# bcm2837_lpa register map
Vendor: BROADCOM; Series: BCM2837; File version: A
CPU: CA72 r0p0, little endian, MPU, FPU, 2 interrupt priority bits
Registers are 32-bit, read-write, reset 0x0 unless marked. A register's access mark holds for its fields unless they carry their own. Offsets are from the block's base; [hi:lo] are bit positions; {n}, {i} and the like mark numbered series.

## SPI0 — Broadcom SPI Controller
Base 0x3F204000
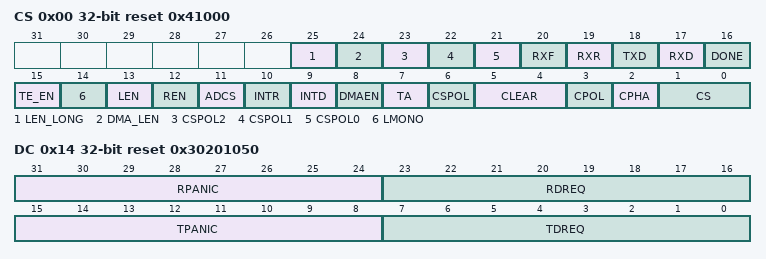
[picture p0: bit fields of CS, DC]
0x00 CS reset 0x41000 — Control and Status
  [25] LEN_LONG — Enable long data word in LoSSI mode
  [24] DMA_LEN — Enable DMA in LoSSI mode
  [23] CSPOL2 — Chip select 2 polarity
  [22] CSPOL1 — Chip select 1 polarity
  [21] CSPOL0 — Chip select 0 polarity
  [20] RXF ro — RX FIFO full
  [19] RXR ro — RX FIFO has data to be read
  [18] TXD ro — TX FIFO can accept data
  [17] RXD ro — RX FIFO contains data
  [16] DONE ro — Transfer is done
  [15] TE_EN
  [14] LMONO
  [13] LEN — LoSSI enable
  [12] REN — Read enable
  [11] ADCS — Automatically deassert chip select
  [10] INTR — Interrupt on RX
  [9] INTD — Interrupt on done
  [8] DMAEN — Enable DMA
  [7] TA — Transfer active
  [6] CSPOL — Chip select polarity
  [5:4] CLEAR — Clear the FIFO(s)
    1=TX; 2=RX; 3=BOTH
  [3] CPOL — Clock polarity
  [2] CPHA — Clock phase
  [1:0] CS — Chip select
0x04 FIFO — FIFO access
  [31:0] DATA
0x08 CLK — Clock divider
  [15:0] CDIV
0x0C DLEN — Data length
  [15:0] DLEN
0x10 LTOH reset 0x1 — LoSSI output hold delay
  [3:0] TOH — Output hold delay
0x14 DC reset 0x30201050
  [31:24] RPANIC — DMA read panic threshold
  [23:16] RDREQ — DMA read request threshold
  [15:8] TPANIC — DMA write panic threshold
  [7:0] TDREQ — DMA Write request threshold

## BSC0 — Broadcom Serial Controller (I2C compatible)
Base 0x3F205000
Same registers: BSC1 0x3F804000, BSC2 0x3F805000
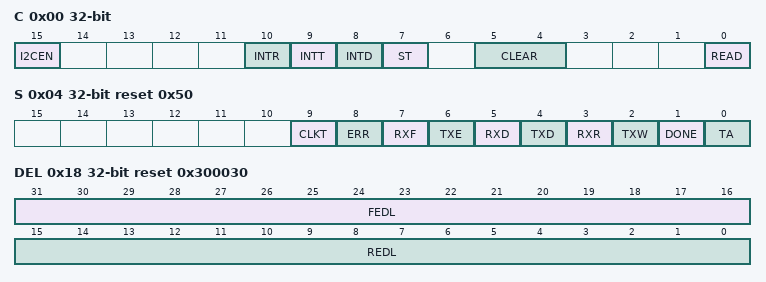
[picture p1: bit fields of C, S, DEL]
0x00 C — Control
  [15] I2CEN — I2C Enable
  [10] INTR — Interrupt on RX
  [9] INTT — Interrupt on TX
  [8] INTD — Interrupt on done
  [7] ST — Start transfer
  [5:4] CLEAR — Clear the FIFO
  [0] READ — Transfer is read
0x04 S reset 0x50 — Status
  [9] CLKT write-1-clears — Clock stretch timeout
  [8] ERR write-1-clears — Error: No ack
  [7] RXF ro — FIFO is full. Can't receive anything else
  [6] TXE ro — FIFO is empty. Nothing to transmit
  [5] RXD ro — FIFO contains at least one byte
  [4] TXD ro — FIFO has space for at least one byte
  [3] RXR ro — FIFO needs to be read
  [2] TXW ro — FIFO needs to be written
  [1] DONE write-1-clears — Transfer done
  [0] TA ro — Transfer active
0x08 DLEN — Data length
  [15:0] DLEN
0x0C A — Slave address
  [6:0] ADDR
0x10 FIFO — Data FIFO
  [7:0] DATA — Access the FIFO
0x14 DIV reset 0x5DC — Clock divider
  [15:0] CDIV — Divide the source clock
0x18 DEL reset 0x300030 — Data delay (Values must be under CDIV / 2)
  [31:16] FEDL — Delay before reading after a falling edge
  [15:0] REDL — Delay before reading after a rising edge
0x1C CLKT — Clock stretch timeout (broken on 283x)
  [15:0] TOUT — Number of SCL clock cycles to wait

## PWM0 — Broadcom PWM
Base 0x3F20C000
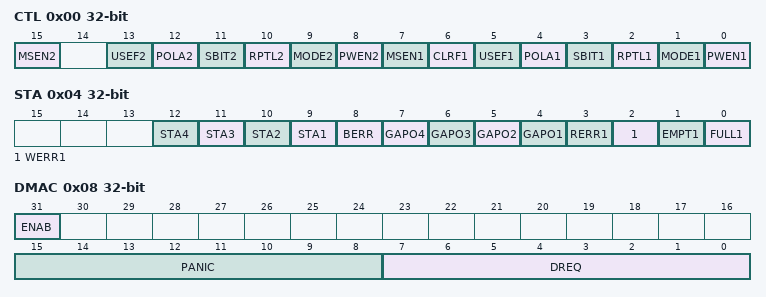
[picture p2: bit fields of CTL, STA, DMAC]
0x00 CTL — Control
  [15] MSEN2 — M/S mode for channel 2
  [13] USEF2 — Use FIFO for channel 2
  [12] POLA2 — Channel 2 polarity inverted
  [11] SBIT2 — State when not transmitting on channel 2
  [10] RPTL2 — Repeat last value from FIFO for channel 2
  [9] MODE2 — Channel 2 mode
    0=PWM; 1=SERIAL
  [8] PWEN2 — Enable channel 2
  [7] MSEN1 — M/S mode for channel 1
  [6] CLRF1 — Clear FIFO
  [5] USEF1 — Use FIFO for channel 1
  [4] POLA1 — Channel 1 polarity inverted
  [3] SBIT1 — State when not transmitting on channel 1
  [2] RPTL1 — Repeat last value from FIFO for channel 1
  [1] MODE1 — Channel 1 mode
    0=PWM; 1=SERIAL
  [0] PWEN1 — Enable channel 1
0x04 STA — Status
  [n+8] STA{n} (n=1..4) — Channel {n} state
  [8] BERR — Bus error
  [n+3] GAPO{n} (n=1..4) — Channel {n} gap occurred
  [3] RERR1 — FIFO read error
  [2] WERR1 — FIFO write error
  [1] EMPT1 — FIFO empty
  [0] FULL1 — FIFO full
0x08 DMAC — DMA control
  [31] ENAB — DMA enabled
  [15:8] PANIC — DMA threshold for panic signal
  [7:0] DREQ — DMA threshold for DREQ signal
0x10 RNG1 reset 0x20 — Range for channel 1
0x14 DAT1 — Channel 1 data
0x18 FIF1 wo — FIFO input
0x20 RNG2 reset 0x20 — Range for channel 2
0x24 DAT2 — Channel 2 data
